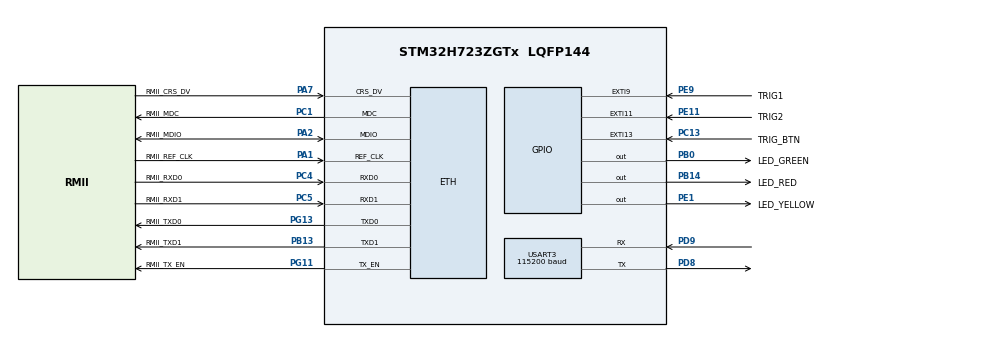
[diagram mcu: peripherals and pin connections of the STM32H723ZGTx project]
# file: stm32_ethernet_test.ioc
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CORTEX_M7.AccessPermission_S-Cortex_Memory_Protection_Unit_Region1_Settings_S=MPU_REGION_FULL_ACCESS
CORTEX_M7.BaseAddress_S-Cortex_Memory_Protection_Unit_Region1_Settings_S=0x30000000
CORTEX_M7.CPU_DCache=Enabled
CORTEX_M7.CPU_ICache=Enabled
CORTEX_M7.DisableExec_S-Cortex_Memory_Protection_Unit_Region1_Settings_S=MPU_INSTRUCTION_ACCESS_DISABLE
CORTEX_M7.Enable_S-Cortex_Memory_Protection_Unit_Region1_Settings_S=MPU_REGION_ENABLE
CORTEX_M7.IsBufferable_S-Cortex_Memory_Protection_Unit_Region1_Settings_S=MPU_ACCESS_NOT_BUFFERABLE
CORTEX_M7.IsCacheable_S-Cortex_Memory_Protection_Unit_Region1_Settings_S=MPU_ACCESS_NOT_CACHEABLE
CORTEX_M7.IsShareable_S-Cortex_Memory_Protection_Unit_Region1_Settings_S=MPU_ACCESS_SHAREABLE
CORTEX_M7.MPU_Control=MPU_PRIVILEGED_DEFAULT
CORTEX_M7.Size_S-Cortex_Memory_Protection_Unit_Region1_Settings_S=MPU_REGION_SIZE_32KB
CORTEX_M7.SubRegionDisable_S-Cortex_Memory_Protection_Unit_Region1_Settings_S=0x0
CORTEX_M7.TypeExtField_S-Cortex_Memory_Protection_Unit_Region1_Settings_S=MPU_TEX_LEVEL1
CORTEX_M7.default_mode_Activation=1
ETH.MediaInterface=HAL_ETH_RMII_MODE
LWIP.BSP.number=1
LWIP.GATEWAY_ADDRESS=192.168.1.1
LWIP.IP_ADDRESS=192.168.1.10
LWIP.LWIP_DHCP=0
LWIP.NETMASK_ADDRESS=255.255.255.0
LWIP.NO_SYS=1
LWIP.Version=v2.2.1_Cube
LWIP0.BSP.STBoard=false
LWIP0.BSP.api=BSP_COMPONENT_DRIVER
LWIP0.BSP.component=LAN8742
LWIP0.BSP.instance=LAN8742
LWIP0.BSP.name=Driver_PHY
LWIP0.BSP.solution=LAN8742
Mcu.Family=STM32H7
Mcu.Name=STM32H723ZGTx
Mcu.Package=LQFP144
NVIC.ETH_IRQn=true\:5\:0\:false\:false\:true\:true\:true\:true
NVIC.EXTI15_10_IRQn=true\:0\:0\:false\:false\:true\:true\:true\:true
NVIC.EXTI9_5_IRQn=true\:0\:0\:false\:false\:true\:true\:true\:true
NVIC.PriorityGroup=NVIC_PRIORITYGROUP_4
PA1.GPIO_Label=RMII_REF_CLK
PA1.Mode=RMII
PA1.Signal=ETH_REF_CLK
PA13(JTMS/SWDIO).GPIO_Label=SWDIO
PA13(JTMS/SWDIO).Signal=DEBUG_JTMS-SWDIO
PA14(JTCK/SWCLK).GPIO_Label=SWCLK
PA14(JTCK/SWCLK).Signal=DEBUG_JTCK-SWCLK
PA2.GPIO_Label=RMII_MDIO
PA2.Mode=RMII
PA2.Signal=ETH_MDIO
PA7.GPIO_Label=RMII_CRS_DV
PA7.Mode=RMII
PA7.Signal=ETH_CRS_DV
PB0.GPIO_Label=LED_GREEN
PB0.Signal=GPIO_Output
PB13.GPIO_Label=RMII_TXD1
PB13.Mode=RMII
PB13.Signal=ETH_TXD1
PB14.GPIO_Label=LED_RED
PB14.Signal=GPIO_Output
PC1.GPIO_Label=RMII_MDC
PC1.Mode=RMII
PC1.Signal=ETH_MDC
PC13.GPIO_Label=TRIG_BTN
PC13.GPIO_ModeDefaultEXTI=GPIO_MODE_IT_RISING
PC13.GPIO_PuPd=GPIO_NOPULL
PC13.Signal=GPXTI13
PC14-OSC32_IN.Signal=RCC_OSC32_IN
PC15-OSC32_OUT.Signal=RCC_OSC32_OUT
PC4.GPIO_Label=RMII_RXD0
PC4.Mode=RMII
PC4.Signal=ETH_RXD0
PC5.GPIO_Label=RMII_RXD1
PC5.Mode=RMII
PC5.Signal=ETH_RXD1
PD8.Mode=Asynchronous
PD8.Signal=USART3_TX
PD9.Mode=Asynchronous
PD9.Signal=USART3_RX
PE1.GPIO_Label=LED_YELLOW
PE1.Signal=GPIO_Output
PE11.GPIO_Label=TRIG2
PE11.GPIO_ModeDefaultEXTI=GPIO_MODE_IT_RISING
PE11.GPIO_PuPd=GPIO_PULLDOWN
PE11.Signal=GPXTI11
PE9.GPIO_Label=TRIG1
PE9.GPIO_ModeDefaultEXTI=GPIO_MODE_IT_RISING
PE9.GPIO_PuPd=GPIO_PULLDOWN
PE9.Signal=GPXTI9
PG11.GPIO_Label=RMII_TX_EN
PG11.Mode=RMII
PG11.Signal=ETH_TX_EN
PG13.GPIO_Label=RMII_TXD0
PG13.Mode=RMII
PG13.Signal=ETH_TXD0
ProjectManager.HeapSize=0x200
ProjectManager.StackSize=0x400
ProjectManager.TargetToolchain=CMake
RCC.ADCFreq_Value=608000000
RCC.APB1Freq_Value=137500000
RCC.APB2Freq_Value=137500000
RCC.APB3Freq_Value=137500000
RCC.APB4Freq_Value=137500000
RCC.CortexFreq_Value=550000000
RCC.D1PPRE=RCC_APB3_DIV2
RCC.D2PPRE1=RCC_APB1_DIV2
RCC.D2PPRE2=RCC_APB2_DIV2
RCC.D3PPRE=RCC_APB4_DIV2
RCC.DIVM1=32
RCC.DIVM2=1
RCC.DIVN1=275
RCC.DIVN2=19
RCC.DIVP1=1
RCC.DIVQ1=4
RCC.HCLKFreq_Value=275000000
RCC.HPRE=RCC_HCLK_DIV2
RCC.HSE_VALUE=8000000
RCC.PLLFRACN=0
RCC.SYSCLKFreq_VALUE=550000000
RCC.SYSCLKSource=RCC_SYSCLKSOURCE_PLLCLK
RCC.USBCLockSelection=RCC_USBCLKSOURCE_HSI48
RCC.USBFreq_Value=48000000
USART3.BaudRate=115200
USART3.VirtualMode-Asynchronous=VM_ASYNC
VP_LWIP_VS_Enabled.Mode=Enabled
board=NUCLEO-H723ZG

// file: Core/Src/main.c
/* USER CODE BEGIN Header */
/**
  ******************************************************************************
  * @file           : main.c
  * @brief          : Main program body
  ******************************************************************************
  * @attention
  *
  * Copyright (c) 2026 STMicroelectronics.
  * All rights reserved.
  *
  * This software is licensed under terms that can be found in the LICENSE file
  * in the root directory of this software component.
  * If no LICENSE file comes with this software, it is provided AS-IS.
  *
  ******************************************************************************
  */
/* USER CODE END Header */
#include "main.h"
#include "lwip.h"

/* USER CODE BEGIN Includes */
#include "cmd_server.h"
#include "eth_log.h"
#include "ptp.h"
#include "trig_events.h"
/* USER CODE END Includes */

UART_HandleTypeDef huart3;

void SystemClock_Config(void);
static void MPU_Config(void);
static void MX_GPIO_Init(void);
static void MX_USART3_UART_Init(void);

int main(void)
{

  /* MPU Configuration--------------------------------------------------------*/
  MPU_Config();

  /* Enable the CPU Cache */

  /* Enable I-Cache---------------------------------------------------------*/
  SCB_EnableICache();

  /* Enable D-Cache---------------------------------------------------------*/
  SCB_EnableDCache();

  /* MCU Configuration--------------------------------------------------------*/

  /* Reset of all peripherals, Initializes the Flash interface and the Systick. */
  HAL_Init();

  /* Configure the system clock */
  SystemClock_Config();

  /* Initialize all configured peripherals */
  MX_GPIO_Init();
  MX_LWIP_Init();
  MX_USART3_UART_Init();
  /* USER CODE BEGIN 2 */
  CmdServer_Init();
  EthLog_Init();
  Ptp_Init();
  /* USER CODE END 2 */

  /* Infinite loop */
  /* USER CODE BEGIN WHILE */
  while (1)
  {
    MX_LWIP_Process();
    /* USER CODE END WHILE */

    /* USER CODE BEGIN 3 */
    EthLog_Poll();
    Ptp_Poll();
    TrigEvents_Poll();
    CmdServer_Poll();
  }
  /* USER CODE END 3 */
}

void SystemClock_Config(void)
{
  RCC_OscInitTypeDef RCC_OscInitStruct = {0};
  RCC_ClkInitTypeDef RCC_ClkInitStruct = {0};

  /** Supply configuration update enable
  */
  HAL_PWREx_ConfigSupply(PWR_LDO_SUPPLY);

  /** Configure the main internal regulator output voltage
  */
  __HAL_PWR_VOLTAGESCALING_CONFIG(PWR_REGULATOR_VOLTAGE_SCALE0);

  while(!__HAL_PWR_GET_FLAG(PWR_FLAG_VOSRDY)) {}

  /** Initializes the RCC Oscillators according to the specified parameters
  * in the RCC_OscInitTypeDef structure.
  */
  RCC_OscInitStruct.OscillatorType = RCC_OSCILLATORTYPE_HSI;
  RCC_OscInitStruct.HSIState = RCC_HSI_DIV1;
  RCC_OscInitStruct.HSICalibrationValue = 64;
  RCC_OscInitStruct.PLL.PLLState = RCC_PLL_ON;
  RCC_OscInitStruct.PLL.PLLSource = RCC_PLLSOURCE_HSI;
  RCC_OscInitStruct.PLL.PLLM = 32;
  RCC_OscInitStruct.PLL.PLLN = 275;
  RCC_OscInitStruct.PLL.PLLP = 1;
  RCC_OscInitStruct.PLL.PLLQ = 4;
  RCC_OscInitStruct.PLL.PLLR = 2;
  RCC_OscInitStruct.PLL.PLLRGE = RCC_PLL1VCIRANGE_1;
  RCC_OscInitStruct.PLL.PLLVCOSEL = RCC_PLL1VCOWIDE;
  RCC_OscInitStruct.PLL.PLLFRACN = 0;
  if (HAL_RCC_OscConfig(&RCC_OscInitStruct) != HAL_OK)
  {
    Error_Handler();
  }

  /** Initializes the CPU, AHB and APB buses clocks
  */
  RCC_ClkInitStruct.ClockType = RCC_CLOCKTYPE_HCLK|RCC_CLOCKTYPE_SYSCLK
                              |RCC_CLOCKTYPE_PCLK1|RCC_CLOCKTYPE_PCLK2
                              |RCC_CLOCKTYPE_D3PCLK1|RCC_CLOCKTYPE_D1PCLK1;
  RCC_ClkInitStruct.SYSCLKSource = RCC_SYSCLKSOURCE_PLLCLK;
  RCC_ClkInitStruct.SYSCLKDivider = RCC_SYSCLK_DIV1;
  RCC_ClkInitStruct.AHBCLKDivider = RCC_HCLK_DIV2;
  RCC_ClkInitStruct.APB3CLKDivider = RCC_APB3_DIV2;
  RCC_ClkInitStruct.APB1CLKDivider = RCC_APB1_DIV2;
  RCC_ClkInitStruct.APB2CLKDivider = RCC_APB2_DIV2;
  RCC_ClkInitStruct.APB4CLKDivider = RCC_APB4_DIV2;

  if (HAL_RCC_ClockConfig(&RCC_ClkInitStruct, FLASH_LATENCY_3) != HAL_OK)
  {
    Error_Handler();
  }
}

static void MX_USART3_UART_Init(void)
{

  huart3.Instance = USART3;
  huart3.Init.BaudRate = 115200;
  huart3.Init.WordLength = UART_WORDLENGTH_8B;
  huart3.Init.StopBits = UART_STOPBITS_1;
  huart3.Init.Parity = UART_PARITY_NONE;
  huart3.Init.Mode = UART_MODE_TX_RX;
  huart3.Init.HwFlowCtl = UART_HWCONTROL_NONE;
  huart3.Init.OverSampling = UART_OVERSAMPLING_16;
  huart3.Init.OneBitSampling = UART_ONE_BIT_SAMPLE_DISABLE;
  huart3.Init.ClockPrescaler = UART_PRESCALER_DIV1;
  huart3.AdvancedInit.AdvFeatureInit = UART_ADVFEATURE_NO_INIT;
  if (HAL_UART_Init(&huart3) != HAL_OK)
  {
    Error_Handler();
  }
  if (HAL_UARTEx_SetTxFifoThreshold(&huart3, UART_TXFIFO_THRESHOLD_1_8) != HAL_OK)
  {
    Error_Handler();
  }
  if (HAL_UARTEx_SetRxFifoThreshold(&huart3, UART_RXFIFO_THRESHOLD_1_8) != HAL_OK)
  {
    Error_Handler();
  }
  if (HAL_UARTEx_DisableFifoMode(&huart3) != HAL_OK)
  {
    Error_Handler();
  }

}

static void MX_GPIO_Init(void)
{
  GPIO_InitTypeDef GPIO_InitStruct = {0};

  /* GPIO Ports Clock Enable */
  __HAL_RCC_GPIOC_CLK_ENABLE();
  __HAL_RCC_GPIOA_CLK_ENABLE();
  __HAL_RCC_GPIOB_CLK_ENABLE();
  __HAL_RCC_GPIOE_CLK_ENABLE();
  __HAL_RCC_GPIOD_CLK_ENABLE();
  __HAL_RCC_GPIOG_CLK_ENABLE();

  /*Configure GPIO pin Output Level */
  HAL_GPIO_WritePin(GPIOB, LED_GREEN_Pin|LED_RED_Pin, GPIO_PIN_RESET);

  /*Configure GPIO pin Output Level */
  HAL_GPIO_WritePin(LED_YELLOW_GPIO_Port, LED_YELLOW_Pin, GPIO_PIN_RESET);

  /*Configure GPIO pin : TRIG_BTN_Pin */
  GPIO_InitStruct.Pin = TRIG_BTN_Pin;
  GPIO_InitStruct.Mode = GPIO_MODE_IT_RISING;
  GPIO_InitStruct.Pull = GPIO_NOPULL;
  HAL_GPIO_Init(TRIG_BTN_GPIO_Port, &GPIO_InitStruct);

  /*Configure GPIO pins : LED_GREEN_Pin LED_RED_Pin */
  GPIO_InitStruct.Pin = LED_GREEN_Pin|LED_RED_Pin;
  GPIO_InitStruct.Mode = GPIO_MODE_OUTPUT_PP;
  GPIO_InitStruct.Pull = GPIO_NOPULL;
  GPIO_InitStruct.Speed = GPIO_SPEED_FREQ_LOW;
  HAL_GPIO_Init(GPIOB, &GPIO_InitStruct);

  /*Configure GPIO pins : TRIG1_Pin TRIG2_Pin */
  GPIO_InitStruct.Pin = TRIG1_Pin|TRIG2_Pin;
  GPIO_InitStruct.Mode = GPIO_MODE_IT_RISING;
  GPIO_InitStruct.Pull = GPIO_PULLDOWN;
  HAL_GPIO_Init(GPIOE, &GPIO_InitStruct);

  /*Configure GPIO pin : LED_YELLOW_Pin */
  GPIO_InitStruct.Pin = LED_YELLOW_Pin;
  GPIO_InitStruct.Mode = GPIO_MODE_OUTPUT_PP;
  GPIO_InitStruct.Pull = GPIO_NOPULL;
  GPIO_InitStruct.Speed = GPIO_SPEED_FREQ_LOW;
  HAL_GPIO_Init(LED_YELLOW_GPIO_Port, &GPIO_InitStruct);

  /* EXTI interrupt init*/
  HAL_NVIC_SetPriority(TRIG1_EXTI_IRQn, 0, 0);
  HAL_NVIC_EnableIRQ(TRIG1_EXTI_IRQn);

  HAL_NVIC_SetPriority(TRIG2_EXTI_IRQn, 0, 0);
  HAL_NVIC_EnableIRQ(TRIG2_EXTI_IRQn);

}

 /* MPU Configuration */

void MPU_Config(void)
{
  MPU_Region_InitTypeDef MPU_InitStruct = {0};

  /* Disables the MPU */
  HAL_MPU_Disable();

  /** Initializes and configures the Region and the memory to be protected
  */
  MPU_InitStruct.Enable = MPU_REGION_ENABLE;
  MPU_InitStruct.Number = MPU_REGION_NUMBER0;
  MPU_InitStruct.BaseAddress = 0x0;
  MPU_InitStruct.Size = MPU_REGION_SIZE_4GB;
  MPU_InitStruct.SubRegionDisable = 0x87;
  MPU_InitStruct.TypeExtField = MPU_TEX_LEVEL0;
  MPU_InitStruct.AccessPermission = MPU_REGION_NO_ACCESS;
  MPU_InitStruct.DisableExec = MPU_INSTRUCTION_ACCESS_DISABLE;
  MPU_InitStruct.IsShareable = MPU_ACCESS_SHAREABLE;
  MPU_InitStruct.IsCacheable = MPU_ACCESS_NOT_CACHEABLE;
  MPU_InitStruct.IsBufferable = MPU_ACCESS_NOT_BUFFERABLE;

  HAL_MPU_ConfigRegion(&MPU_InitStruct);

  /** Initializes and configures the Region and the memory to be protected
  */
  MPU_InitStruct.Number = MPU_REGION_NUMBER1;
  MPU_InitStruct.BaseAddress = 0x30000000;
  MPU_InitStruct.Size = MPU_REGION_SIZE_32KB;
  MPU_InitStruct.SubRegionDisable = 0x0;
  MPU_InitStruct.TypeExtField = MPU_TEX_LEVEL1;
  MPU_InitStruct.AccessPermission = MPU_REGION_FULL_ACCESS;

  HAL_MPU_ConfigRegion(&MPU_InitStruct);
  /* Enables the MPU */
  HAL_MPU_Enable(MPU_PRIVILEGED_DEFAULT);

}

void Error_Handler(void)
{
  __disable_irq();
  while (1)
  {
  }
}
